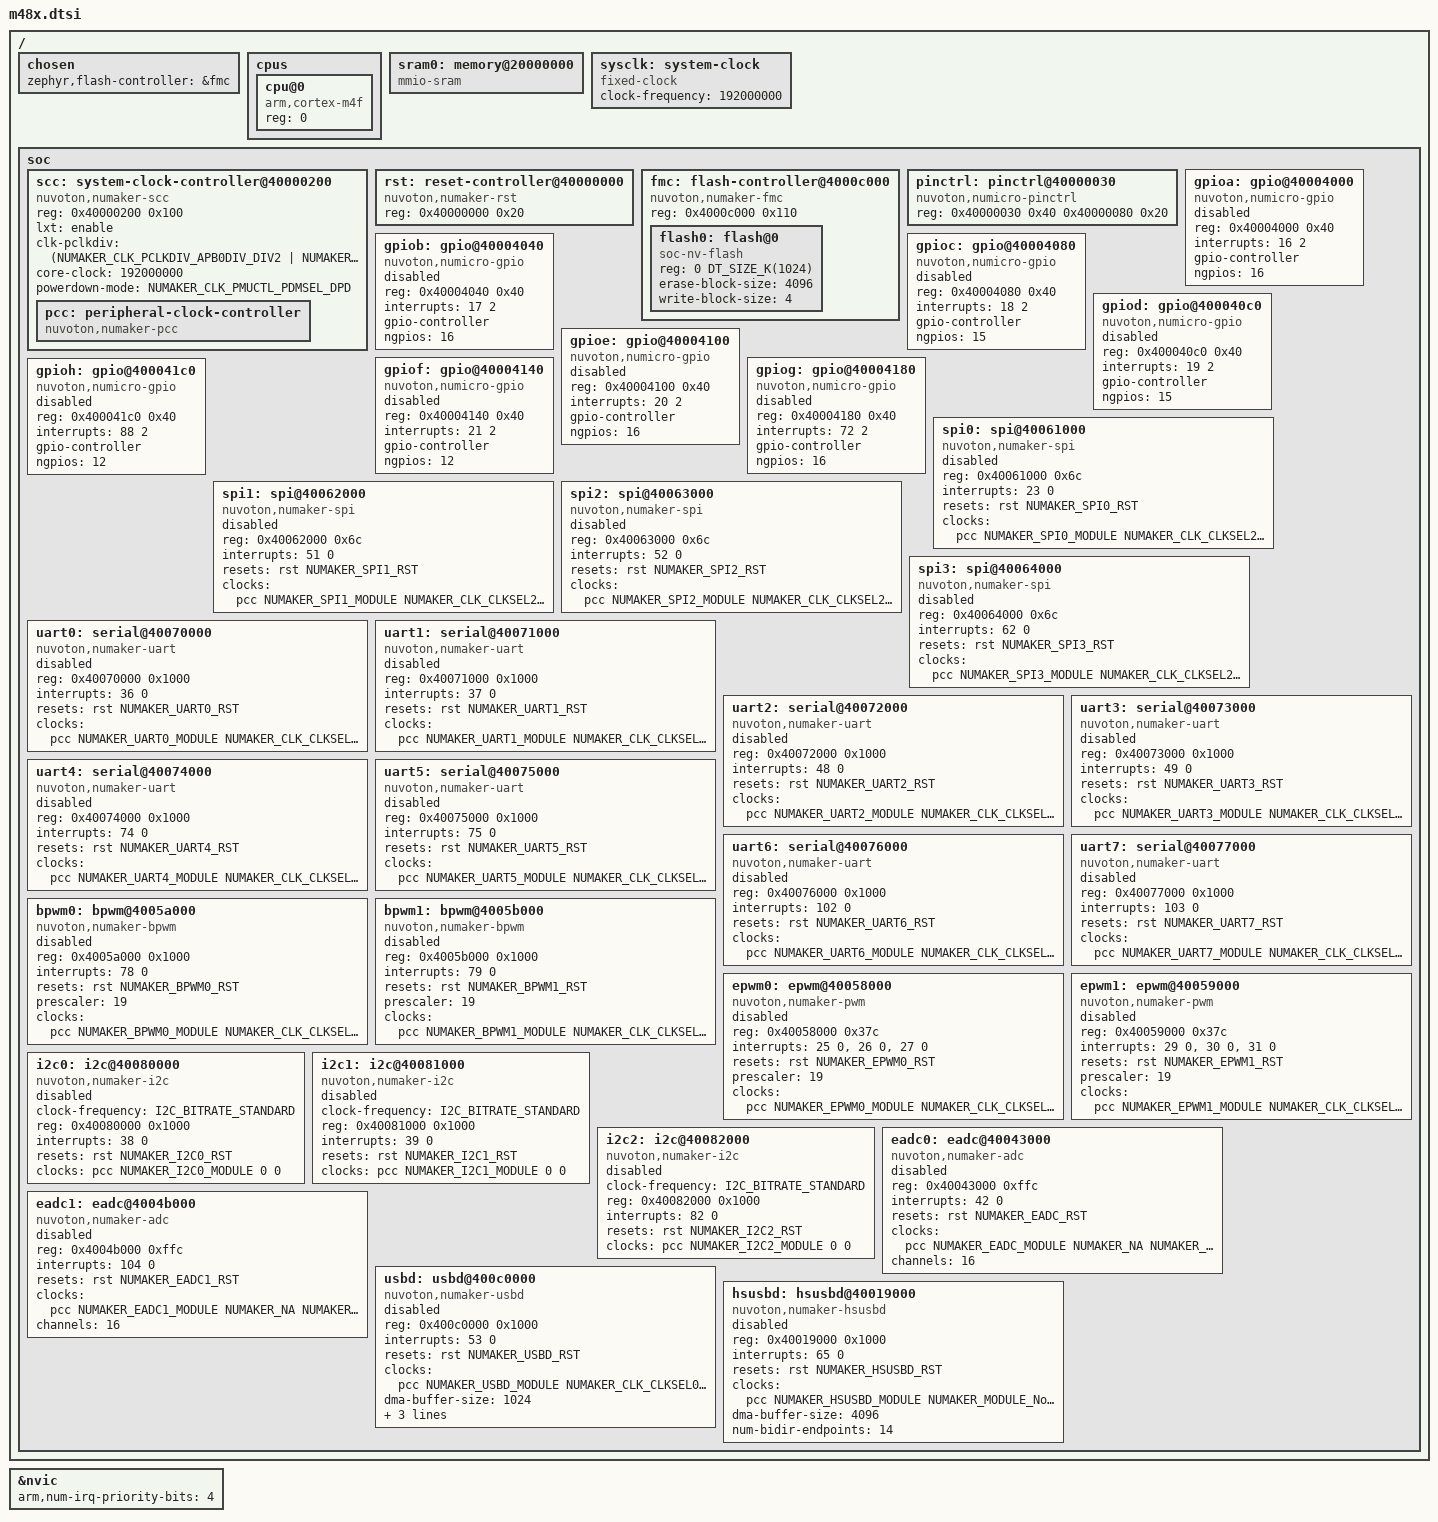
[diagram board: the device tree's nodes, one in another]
/*
 * Copyright (c) 2020 Linumiz
 *
 * SPDX-License-Identifier: Apache-2.0
 */

#include <arm/armv7-m.dtsi>
#include <mem.h>
#include <zephyr/dt-bindings/gpio/gpio.h>

#include <zephyr/dt-bindings/clock/numaker_m48x_clock.h>
#include <zephyr/dt-bindings/reset/numaker_m48x_reset.h>
#include <zephyr/dt-bindings/i2c/i2c.h>

/ {
	chosen {
		zephyr,flash-controller = &fmc;
	};
	
	cpus {
		#address-cells = <1>;
		#size-cells = <0>;

		cpu@0 {
			device_type = "cpu";
			compatible = "arm,cortex-m4f";
			reg = <0>;
		};
	};

	sram0: memory@20000000 {
		compatible = "mmio-sram";
	};

	sysclk: system-clock {
		compatible = "fixed-clock";
		clock-frequency = <192000000>;
		#clock-cells = <0>;
	};

	soc {
		scc: system-clock-controller@40000200 {
			compatible = "nuvoton,numaker-scc";
			reg = <0x40000200 0x100>;
			#clock-cells = <0>;
			/* hxt = "enable"; */
			lxt = "enable";
			clk-pclkdiv = <(NUMAKER_CLK_PCLKDIV_APB0DIV_DIV2 |
					 NUMAKER_CLK_PCLKDIV_APB1DIV_DIV2)>;
			core-clock = <192000000>;
			powerdown-mode = <NUMAKER_CLK_PMUCTL_PDMSEL_DPD>;

			pcc: peripheral-clock-controller {
				compatible = "nuvoton,numaker-pcc";
				#clock-cells = <3>;
			};
		};

		rst: reset-controller@40000000 {
			compatible = "nuvoton,numaker-rst";
			reg = <0x40000000 0x20>;
			#reset-cells = <1>;
			status = "okay";
		};

		fmc: flash-controller@4000c000 {
			compatible = "nuvoton,numaker-fmc";
			reg = <0x4000c000 0x110>;
			#address-cells = <1>;
			#size-cells = <1>;

			flash0: flash@0 {
				compatible = "soc-nv-flash";
				reg = <0 DT_SIZE_K(1024)>;
				erase-block-size = <4096>;
				write-block-size = <4>;
			};
		};

		pinctrl: pinctrl@40000030 {
			compatible = "nuvoton,numicro-pinctrl";
			reg = <0x40000030 0x40
			       0x40000080 0x20>;
			reg-names = "mfp", "mfos";
			status = "okay";
		};

		gpioa: gpio@40004000 {
			compatible = "nuvoton,numicro-gpio";
			reg = <0x40004000 0x40>;
			status = "disabled";
			interrupts = <16 2>;
			gpio-controller;
			#gpio-cells = <2>;
			ngpios = <16>;
		};

		gpiob: gpio@40004040 {
			compatible = "nuvoton,numicro-gpio";
			reg = <0x40004040 0x40>;
			status = "disabled";
			interrupts = <17 2>;
			gpio-controller;
			#gpio-cells = <2>;
			ngpios = <16>;
		};

		gpioc: gpio@40004080 {
			compatible = "nuvoton,numicro-gpio";
			reg = <0x40004080 0x40>;
			status = "disabled";
			interrupts = <18 2>;
			gpio-controller;
			#gpio-cells = <2>;
			ngpios = <15>;
		};

		gpiod: gpio@400040c0 {
			compatible = "nuvoton,numicro-gpio";
			reg = <0x400040c0 0x40>;
			status = "disabled";
			interrupts = <19 2>;
			gpio-controller;
			#gpio-cells = <2>;
			ngpios = <15>;
		};

		gpioe: gpio@40004100 {
			compatible = "nuvoton,numicro-gpio";
			reg = <0x40004100 0x40>;
			status = "disabled";
			interrupts = <20 2>;
			gpio-controller;
			#gpio-cells = <2>;
			ngpios = <16>;
		};

		gpiof: gpio@40004140 {
			compatible = "nuvoton,numicro-gpio";
			reg = <0x40004140 0x40>;
			status = "disabled";
			interrupts = <21 2>;
			gpio-controller;
			#gpio-cells = <2>;
			ngpios = <12>;
		};

		gpiog: gpio@40004180 {
			compatible = "nuvoton,numicro-gpio";
			reg = <0x40004180 0x40>;
			status = "disabled";
			interrupts = <72 2>;
			gpio-controller;
			#gpio-cells = <2>;
			ngpios = <16>;
		};

		gpioh: gpio@400041c0 {
			compatible = "nuvoton,numicro-gpio";
			reg = <0x400041c0 0x40>;
			status = "disabled";
			interrupts = <88 2>;
			gpio-controller;
			#gpio-cells = <2>;
			ngpios = <12>;
		};

		spi0: spi@40061000 {
			compatible = "nuvoton,numaker-spi";
			reg = <0x40061000 0x6c>;
			interrupts = <23 0>;
			resets = <&rst NUMAKER_SPI0_RST>;
			clocks = <&pcc NUMAKER_SPI0_MODULE NUMAKER_CLK_CLKSEL2_SPI0SEL_PLL 0>;
			#address-cells = <1>;
			#size-cells = <0>;
			status = "disabled";
		};

		spi1: spi@40062000 {
			compatible = "nuvoton,numaker-spi";
			reg = <0x40062000 0x6c>;
			interrupts = <51 0>;
			resets = <&rst NUMAKER_SPI1_RST>;
			clocks = <&pcc NUMAKER_SPI1_MODULE NUMAKER_CLK_CLKSEL2_SPI1SEL_PLL 0>;
			#address-cells = <1>;
			#size-cells = <0>;
			status = "disabled";
		};

		spi2: spi@40063000 {
			compatible = "nuvoton,numaker-spi";
			reg = <0x40063000 0x6c>;
			interrupts = <52 0>;
			resets = <&rst NUMAKER_SPI2_RST>;
			clocks = <&pcc NUMAKER_SPI2_MODULE NUMAKER_CLK_CLKSEL2_SPI2SEL_PLL 0>;
			#address-cells = <1>;
			#size-cells = <0>;
			status = "disabled";
		};

		spi3: spi@40064000 {
			compatible = "nuvoton,numaker-spi";
			reg = <0x40064000 0x6c>;
			interrupts = <62 0>;
			resets = <&rst NUMAKER_SPI3_RST>;
			clocks = <&pcc NUMAKER_SPI3_MODULE NUMAKER_CLK_CLKSEL2_SPI3SEL_PLL 0>;
			#address-cells = <1>;
			#size-cells = <0>;
			status = "disabled";
		};

		uart0: serial@40070000 {
			compatible = "nuvoton,numaker-uart";
			reg = <0x40070000 0x1000>;
			interrupts = <36 0>;
			resets = <&rst NUMAKER_UART0_RST>;
			clocks = <&pcc NUMAKER_UART0_MODULE NUMAKER_CLK_CLKSEL1_UART0SEL_PLL
				  NUMAKER_CLK_CLKDIV0_UART0(1)>;
			status = "disabled";
		};

		uart1: serial@40071000 {
			compatible = "nuvoton,numaker-uart";
			reg = <0x40071000 0x1000>;
			interrupts = <37 0>;
			resets = <&rst NUMAKER_UART1_RST>;
			clocks = <&pcc NUMAKER_UART1_MODULE NUMAKER_CLK_CLKSEL1_UART1SEL_PLL
				  NUMAKER_CLK_CLKDIV0_UART1(1)>;
			status = "disabled";
		};

		uart2: serial@40072000 {
			compatible = "nuvoton,numaker-uart";
			reg = <0x40072000 0x1000>;
			interrupts = <48 0>;
			resets = <&rst NUMAKER_UART2_RST>;
			clocks = <&pcc NUMAKER_UART2_MODULE NUMAKER_CLK_CLKSEL3_UART2SEL_PLL
				  NUMAKER_CLK_CLKDIV4_UART2(1)>;
			status = "disabled";
		};

		uart3: serial@40073000 {
			compatible = "nuvoton,numaker-uart";
			reg = <0x40073000 0x1000>;
			interrupts = <49 0>;
			resets = <&rst NUMAKER_UART3_RST>;
			clocks = <&pcc NUMAKER_UART3_MODULE NUMAKER_CLK_CLKSEL3_UART3SEL_PLL
				  NUMAKER_CLK_CLKDIV4_UART3(1)>;
			status = "disabled";
		};

		uart4: serial@40074000 {
			compatible = "nuvoton,numaker-uart";
			reg = <0x40074000 0x1000>;
			interrupts = <74 0>;
			resets = <&rst NUMAKER_UART4_RST>;
			clocks = <&pcc NUMAKER_UART4_MODULE NUMAKER_CLK_CLKSEL3_UART4SEL_PLL
				  NUMAKER_CLK_CLKDIV4_UART4(1)>;
			status = "disabled";
		};

		uart5: serial@40075000 {
			compatible = "nuvoton,numaker-uart";
			reg = <0x40075000 0x1000>;
			interrupts = <75 0>;
			resets = <&rst NUMAKER_UART5_RST>;
			clocks = <&pcc NUMAKER_UART5_MODULE NUMAKER_CLK_CLKSEL3_UART5SEL_PLL
				  NUMAKER_CLK_CLKDIV4_UART5(1)>;
			status = "disabled";
		};

		uart6: serial@40076000 {
			compatible = "nuvoton,numaker-uart";
			reg = <0x40076000 0x1000>;
			interrupts = <102 0>;
			resets = <&rst NUMAKER_UART6_RST>;
			clocks = <&pcc NUMAKER_UART6_MODULE NUMAKER_CLK_CLKSEL3_UART6SEL_PLL
				  NUMAKER_CLK_CLKDIV4_UART6(1)>;
			status = "disabled";
		};

		uart7: serial@40077000 {
			compatible = "nuvoton,numaker-uart";
			reg = <0x40077000 0x1000>;
			interrupts = <103 0>;
			resets = <&rst NUMAKER_UART7_RST>;
			clocks = <&pcc NUMAKER_UART7_MODULE NUMAKER_CLK_CLKSEL3_UART7SEL_PLL
				  NUMAKER_CLK_CLKDIV4_UART7(1)>;
			status = "disabled";
		};

		bpwm0: bpwm@4005a000 {
			compatible = "nuvoton,numaker-bpwm";
			reg = <0x4005a000 0x1000>;
			interrupts = <78 0>;
			interrupt-names = "bpwm0";
			resets = <&rst NUMAKER_BPWM0_RST>;
			prescaler = <19>;
			clocks = <&pcc NUMAKER_BPWM0_MODULE NUMAKER_CLK_CLKSEL2_BPWM0SEL_PCLK0 0>;
			#pwm-cells = <3>;
			status = "disabled";
		};

		bpwm1: bpwm@4005b000 {
			compatible = "nuvoton,numaker-bpwm";
			reg = <0x4005b000 0x1000>;
			interrupts = <79 0>;
			interrupt-names = "bpwm1";
			resets = <&rst NUMAKER_BPWM1_RST>;
			prescaler = <19>;
			clocks = <&pcc NUMAKER_BPWM1_MODULE NUMAKER_CLK_CLKSEL2_BPWM1SEL_PCLK1 0>;
			#pwm-cells = <3>;
			status = "disabled";
		};

		epwm0: epwm@40058000 {
			compatible = "nuvoton,numaker-pwm";
			reg = <0x40058000 0x37c>;
			interrupts = <25 0>, <26 0>, <27 0>;
			interrupt-names = "pair0", "pair1", "pair2";
			resets = <&rst NUMAKER_EPWM0_RST>;
			prescaler = <19>;
			clocks = <&pcc NUMAKER_EPWM0_MODULE NUMAKER_CLK_CLKSEL2_EPWM0SEL_PCLK0 0>;
			#pwm-cells = <3>;
			status = "disabled";
		};

		epwm1: epwm@40059000 {
			compatible = "nuvoton,numaker-pwm";
			reg = <0x40059000 0x37c>;
			interrupts = <29 0>, <30 0>, <31 0>;
			interrupt-names = "pair0", "pair1", "pair2";
			resets = <&rst NUMAKER_EPWM1_RST>;
			prescaler = <19>;
			clocks = <&pcc NUMAKER_EPWM1_MODULE NUMAKER_CLK_CLKSEL2_EPWM1SEL_PCLK1 0>;
			#pwm-cells = <3>;
			status = "disabled";
		};

		i2c0: i2c@40080000 {
			compatible = "nuvoton,numaker-i2c";
			clock-frequency = <I2C_BITRATE_STANDARD>;
			reg = <0x40080000 0x1000>;
			interrupts = <38 0>;
			resets = <&rst NUMAKER_I2C0_RST>;
			clocks = <&pcc NUMAKER_I2C0_MODULE 0 0>;
			status = "disabled";
			#address-cells = <1>;
			#size-cells = <0>;
		};

		i2c1: i2c@40081000 {
			compatible = "nuvoton,numaker-i2c";
			clock-frequency = <I2C_BITRATE_STANDARD>;
			reg = <0x40081000 0x1000>;
			interrupts = <39 0>;
			resets = <&rst NUMAKER_I2C1_RST>;
			clocks = <&pcc NUMAKER_I2C1_MODULE 0 0>;
			status = "disabled";
			#address-cells = <1>;
			#size-cells = <0>;
		};

		i2c2: i2c@40082000 {
			compatible = "nuvoton,numaker-i2c";
			clock-frequency = <I2C_BITRATE_STANDARD>;
			reg = <0x40082000 0x1000>;
			interrupts = <82 0>;
			resets = <&rst NUMAKER_I2C2_RST>;
			clocks = <&pcc NUMAKER_I2C2_MODULE 0 0>;
			status = "disabled";
			#address-cells = <1>;
			#size-cells = <0>;
		};

		eadc0: eadc@40043000 {
			compatible = "nuvoton,numaker-adc";
			reg = <0x40043000 0xffc>;
			interrupts = <42 0>;
			resets = <&rst NUMAKER_EADC_RST>;
			clocks = <&pcc NUMAKER_EADC_MODULE
				  NUMAKER_NA /* HCLK is the only non-configurable clock source */
				  NUMAKER_CLK_CLKDIV0_EADC(12)>;
			channels = <16>;
			status = "disabled";
			#io-channel-cells = <1>;
		};

		eadc1: eadc@4004b000 {
			compatible = "nuvoton,numaker-adc";
			reg = <0x4004b000 0xffc>;
			interrupts = <104 0>;
			resets = <&rst NUMAKER_EADC1_RST>;
			clocks = <&pcc NUMAKER_EADC1_MODULE
				  NUMAKER_NA /* HCLK is the only non-configurable clock source */
				  NUMAKER_CLK_CLKDIV2_EADC1(12)>;
			channels = <16>;
			status = "disabled";
			#io-channel-cells = <1>;
		};

		usbd: usbd@400c0000 {
			compatible = "nuvoton,numaker-usbd";
			reg = <0x400c0000 0x1000>;
			interrupts = <53 0>;
			resets = <&rst NUMAKER_USBD_RST>;
			clocks = <&pcc NUMAKER_USBD_MODULE NUMAKER_CLK_CLKSEL0_USBSEL_PLL
				  NUMAKER_CLK_CLKDIV0_USB(4)>;
			dma-buffer-size = <1024>;
			dma-buffer-offset = <0x100>;
			status = "disabled";
			num-bidir-endpoints = <12>;
			disallow-iso-in-out-same-number;
		};
		
		hsusbd: hsusbd@40019000 {
			compatible = "nuvoton,numaker-hsusbd";
			reg = <0x40019000 0x1000>;
			interrupts = <65 0>;
			resets = <&rst NUMAKER_HSUSBD_RST>; 
			clocks = <&pcc NUMAKER_HSUSBD_MODULE NUMAKER_MODULE_NoMsk
				  NUMAKER_MODULE_NoMsk>;
			dma-buffer-size = <4096>;
			status = "disabled";
			/* 2 more for Control OUT/IN */
			num-bidir-endpoints = <14>;
		};
	};
};

&nvic {
	arm,num-irq-priority-bits = <4>;
};
